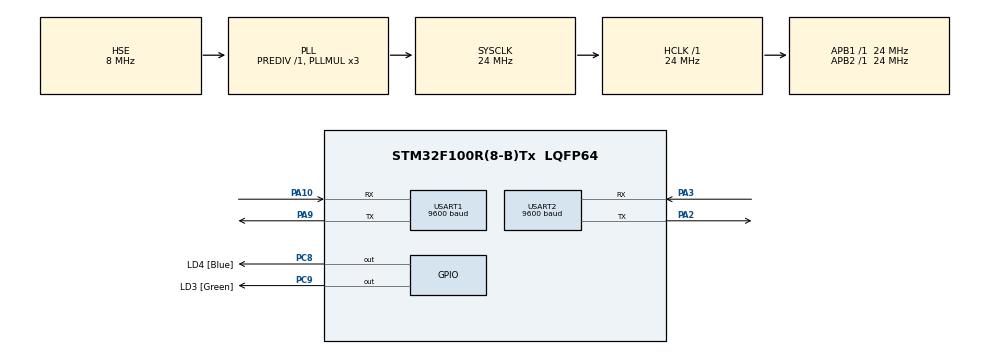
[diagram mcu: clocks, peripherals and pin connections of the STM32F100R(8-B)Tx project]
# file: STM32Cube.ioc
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Mcu.Family=STM32F1
Mcu.Name=STM32F100R(8-B)Tx
Mcu.Package=LQFP64
NVIC.PriorityGroup=NVIC_PRIORITYGROUP_4
PA0-WKUP.Mode=SYS_WakeUp0
PA0-WKUP.Signal=SYS_WKUP
PA10.Mode=Asynchronous
PA10.Signal=USART1_RX
PA13.GPIO_Label=TMS_SWDIO
PA13.Mode=Serial_Wire
PA13.Signal=SYS_JTMS-SWDIO
PA14.GPIO_Label=TCK_SWCLK
PA14.Mode=Serial_Wire
PA14.Signal=SYS_JTCK-SWCLK
PA2.Mode=Asynchronous
PA2.Signal=USART2_TX
PA3.Mode=Asynchronous
PA3.Signal=USART2_RX
PA9.Mode=Asynchronous
PA9.Signal=USART1_TX
PC14-OSC32_IN.Mode=LSE-External-Oscillator
PC14-OSC32_IN.Signal=RCC_OSC32_IN
PC15-OSC32_OUT.Mode=LSE-External-Oscillator
PC15-OSC32_OUT.Signal=RCC_OSC32_OUT
PC8.GPIO_Label=LD4 [Blue]
PC8.Signal=GPIO_Output
PC9.GPIO_Label=LD3 [Green]
PC9.Signal=GPIO_Output
PD0-OSC_IN.Mode=HSE-External-Oscillator
PD0-OSC_IN.Signal=RCC_OSC_IN
PD1-OSC_OUT.Mode=HSE-External-Oscillator
PD1-OSC_OUT.Signal=RCC_OSC_OUT
ProjectManager.HeapSize=0x200
ProjectManager.StackSize=0x400
ProjectManager.TargetToolchain=MDK-ARM V5
RCC.AHBFreq_Value=24000000
RCC.APB1Freq_Value=24000000
RCC.APB1TimFreq_Value=24000000
RCC.APB2Freq_Value=24000000
RCC.APB2TimFreq_Value=24000000
RCC.HCLKFreq_Value=24000000
RCC.PLLMUL=RCC_PLL_MUL3
RCC.PLLSource=RCC_PLLSOURCE_HSE
RCC.SYSCLKFreq_VALUE=24000000
RCC.SYSCLKSource=RCC_SYSCLKSOURCE_PLLCLK
USART1.BaudRate=9600
USART1.VirtualMode=VM_ASYNC
USART2.BaudRate=9600
USART2.VirtualMode=VM_ASYNC
board=STM32VLDISCOVERY

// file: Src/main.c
/* USER CODE BEGIN Header */
/**
  ******************************************************************************
  * @file           : main.c
  * @brief          : Main program body
  ******************************************************************************
  ** This notice applies to any and all portions of this file
  * that are not between comment pairs USER CODE BEGIN and
  * USER CODE END. Other portions of this file, whether
  * inserted by the user or by software development tools
  * are owned by their respective copyright owners.
  *
  * COPYRIGHT(c) 2019 STMicroelectronics
  *
  * Redistribution and use in source and binary forms, with or without modification,
  * are permitted provided that the following conditions are met:
  *   1. Redistributions of source code must retain the above copyright notice,
  *      this list of conditions and the following disclaimer.
  *   2. Redistributions in binary form must reproduce the above copyright notice,
  *      this list of conditions and the following disclaimer in the documentation
  *      and/or other materials provided with the distribution.
  *   3. Neither the name of STMicroelectronics nor the names of its contributors
  *      may be used to endorse or promote products derived from this software
  *      without specific prior written permission.
  *
  * THIS SOFTWARE IS PROVIDED BY THE COPYRIGHT HOLDERS AND CONTRIBUTORS "AS IS"
  * AND ANY EXPRESS OR IMPLIED WARRANTIES, INCLUDING, BUT NOT LIMITED TO, THE
  * IMPLIED WARRANTIES OF MERCHANTABILITY AND FITNESS FOR A PARTICULAR PURPOSE ARE
  * DISCLAIMED. IN NO EVENT SHALL THE COPYRIGHT HOLDER OR CONTRIBUTORS BE LIABLE
  * FOR ANY DIRECT, INDIRECT, INCIDENTAL, SPECIAL, EXEMPLARY, OR CONSEQUENTIAL
  * DAMAGES (INCLUDING, BUT NOT LIMITED TO, PROCUREMENT OF SUBSTITUTE GOODS OR
  * SERVICES; LOSS OF USE, DATA, OR PROFITS; OR BUSINESS INTERRUPTION) HOWEVER
  * CAUSED AND ON ANY THEORY OF LIABILITY, WHETHER IN CONTRACT, STRICT LIABILITY,
  * OR TORT (INCLUDING NEGLIGENCE OR OTHERWISE) ARISING IN ANY WAY OUT OF THE USE
  * OF THIS SOFTWARE, EVEN IF ADVISED OF THE POSSIBILITY OF SUCH DAMAGE.
  *
  ******************************************************************************
  */
/* USER CODE END Header */

#include "main.h"
#include <string.h>
#include "uart.h"
#include <stdlib.h>
#include <stdio.h>
#include <inttypes.h>

UART_HandleTypeDef huart1;
UART_HandleTypeDef huart2;

void SystemClock_Config(void);
static void MX_GPIO_Init(void);
static void MX_USART1_UART_Init(void);
static void MX_USART2_UART_Init(void);

int main(void)
{

  /* MCU Configuration--------------------------------------------------------*/

  /* Reset of all peripherals, Initializes the Flash interface and the Systick. */
  HAL_Init();

  /* Configure the system clock */
  SystemClock_Config();

  /* Initialize all configured peripherals */
  MX_GPIO_Init();
  MX_USART1_UART_Init();
  MX_USART2_UART_Init();

  /* USER CODE BEGIN 2 */
	uint8_t data[8] = {0x7E,0x00,0x04,0x08,0x01,0x48,0x56,0x58};
	char c[25];
	uint8_t dataout[11];

  /* USER CODE END 2 */

  /* Infinite loop */
  while (1)
  {
  /*print_str("wassup \n\r");*/

//	sprintf(c,"%su", data);
//	print_str(c);
	uart_send_message(data);
	dataout = uart_receive_message(dataout);

	}
  /* USER CODE END 3 */
}

void SystemClock_Config(void)
{
  RCC_OscInitTypeDef RCC_OscInitStruct = {0};
  RCC_ClkInitTypeDef RCC_ClkInitStruct = {0};

  /**Initializes the CPU, AHB and APB busses clocks
  */
  RCC_OscInitStruct.OscillatorType = RCC_OSCILLATORTYPE_HSE;
  RCC_OscInitStruct.HSEState = RCC_HSE_ON;
  RCC_OscInitStruct.HSEPredivValue = RCC_HSE_PREDIV_DIV1;
  RCC_OscInitStruct.PLL.PLLState = RCC_PLL_ON;
  RCC_OscInitStruct.PLL.PLLSource = RCC_PLLSOURCE_HSE;
  RCC_OscInitStruct.PLL.PLLMUL = RCC_PLL_MUL3;
  if (HAL_RCC_OscConfig(&RCC_OscInitStruct) != HAL_OK)
  {
    Error_Handler();
  }
  /**Initializes the CPU, AHB and APB busses clocks
  */
  RCC_ClkInitStruct.ClockType = RCC_CLOCKTYPE_HCLK|RCC_CLOCKTYPE_SYSCLK
                              |RCC_CLOCKTYPE_PCLK1|RCC_CLOCKTYPE_PCLK2;
  RCC_ClkInitStruct.SYSCLKSource = RCC_SYSCLKSOURCE_PLLCLK;
  RCC_ClkInitStruct.AHBCLKDivider = RCC_SYSCLK_DIV1;
  RCC_ClkInitStruct.APB1CLKDivider = RCC_HCLK_DIV1;
  RCC_ClkInitStruct.APB2CLKDivider = RCC_HCLK_DIV1;

  if (HAL_RCC_ClockConfig(&RCC_ClkInitStruct, FLASH_LATENCY_0) != HAL_OK)
  {
    Error_Handler();
  }
}

static void MX_USART1_UART_Init(void)
{

  huart1.Instance = USART1;
  huart1.Init.BaudRate = 9600;
  huart1.Init.WordLength = UART_WORDLENGTH_8B;
  huart1.Init.StopBits = UART_STOPBITS_1;
  huart1.Init.Parity = UART_PARITY_NONE;
  huart1.Init.Mode = UART_MODE_TX_RX;
  huart1.Init.HwFlowCtl = UART_HWCONTROL_NONE;
  huart1.Init.OverSampling = UART_OVERSAMPLING_16;
  if (HAL_UART_Init(&huart1) != HAL_OK)
  {
    Error_Handler();
  }

}

static void MX_USART2_UART_Init(void)
{

  huart2.Instance = USART2;
  huart2.Init.BaudRate = 9600;
  huart2.Init.WordLength = UART_WORDLENGTH_8B;
  huart2.Init.StopBits = UART_STOPBITS_1;
  huart2.Init.Parity = UART_PARITY_NONE;
  huart2.Init.Mode = UART_MODE_TX_RX;
  huart2.Init.HwFlowCtl = UART_HWCONTROL_NONE;
  huart2.Init.OverSampling = UART_OVERSAMPLING_16;
  if (HAL_UART_Init(&huart2) != HAL_OK)
  {
    Error_Handler();
  }

}

static void MX_GPIO_Init(void)
{
  GPIO_InitTypeDef GPIO_InitStruct = {0};

  /* GPIO Ports Clock Enable */
  __HAL_RCC_GPIOC_CLK_ENABLE();
  __HAL_RCC_GPIOD_CLK_ENABLE();
  __HAL_RCC_GPIOA_CLK_ENABLE();

  /*Configure GPIO pin Output Level */
  HAL_GPIO_WritePin(GPIOC, LD4_Pin|LD3_Pin, GPIO_PIN_RESET);

  /*Configure GPIO pins : LD4_Pin LD3_Pin */
  GPIO_InitStruct.Pin = LD4_Pin|LD3_Pin;
  GPIO_InitStruct.Mode = GPIO_MODE_OUTPUT_PP;
  GPIO_InitStruct.Pull = GPIO_NOPULL;
  GPIO_InitStruct.Speed = GPIO_SPEED_FREQ_LOW;
  HAL_GPIO_Init(GPIOC, &GPIO_InitStruct);

}

void Error_Handler(void)
{
}

/************************ (C) COPYRIGHT STMicroelectronics *****END OF FILE****/
